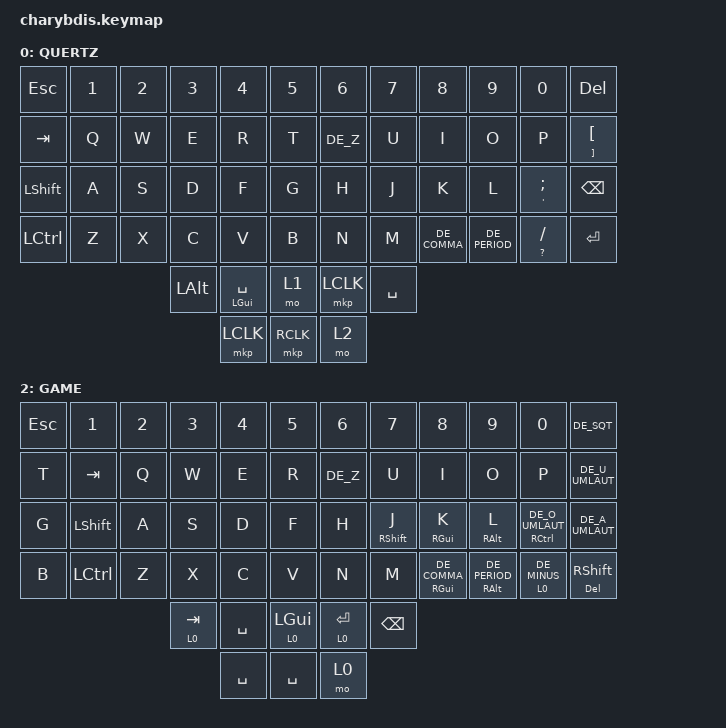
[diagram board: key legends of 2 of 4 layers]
#include "keys_de_swiss.h"
#include <dt-bindings/zmk/mouse.h>
#include <behaviors.dtsi>
#include <dt-bindings/zmk/bt.h>
#include <dt-bindings/zmk/ext_power.h>
#include <dt-bindings/zmk/keys.h>
#include <dt-bindings/zmk/pointing.h>
#include <input/processors.dtsi>
#include <dt-bindings/zmk/input_transform.h>

/ {
    /* ================= COMBOS ================== */

    combos {
        compatible = "zmk,combos";

        to-WIN {
            bindings = <&to 0>;
            key-positions = <50 51>;
            layers = <2 3>;
        };

        to-GAME {
            bindings = <&to 2>;
            key-positions = <47 36>;
            layers = <0 3>;
        };

        to-FN {
            bindings = <&to 3>;
            key-positions = <41 42>;
            layers = <0 2>;
        };

        caps_word {
            bindings = <&caps_word>;
            key-positions = <31 28>;
        };

        // УБРАНЫ мышиные клики через комбо — нестабильная конструкция
    };

    /* ================= BEHAVIORS ================= */

    behaviors {
        hmr: hmr {
            compatible = "zmk,behavior-hold-tap";
            label = "HMR";
            bindings = <&kp>, <&kp>;

            #binding-cells = <2>;
            tapping-term-ms = <190>;
            quick-tap-ms = <175>;
            flavor = "balanced";
            hold-trigger-key-positions = <36 37 38 39 40 41>; // ИСПРАВЛЕНО: только противоположная рука
            hold-trigger-on-release;
        };

        hml: hml {
            compatible = "zmk,behavior-hold-tap";
            label = "HML";
            bindings = <&kp>, <&kp>;

            #binding-cells = <2>;
            tapping-term-ms = <190>;
            quick-tap-ms = <175>;
            flavor = "balanced";
            hold-trigger-key-positions = <0 1 2 3 4 5>; // ИСПРАВЛЕНО: минимальный безопасный список
            hold-trigger-on-release;
        };
    };

    /* ================= TRACKBALL / MOUSE ================= */

    trackball_listener {
        compatible = "zmk,input-listener";
        device = <&trackball_split>;

        snipe {
            layers = <3>; /* Mouse layer */
            input-processors = <&zip_xy_scaler 1 3>;
        };

        scroll {
            layers = <2>; /* Nav layer */
            input-processors = <&zip_xy_scaler 1 3>, <&zip_xy_to_scroll_mapper>, <&zip_scroll_transform (INPUT_TRANSFORM_Y_INVERT)>;
        };
    };

    chosen {
        zmk,matrix_transform = &four_column_transform; /* 4×6 */
    };

    /* ================= KEYMAP ================= */

    keymap {
        compatible = "zmk,keymap";

        default_win_layer {
            label = "QUERTZ";
            bindings = <
&kp ESCAPE      &kp N1  &kp N2  &kp N3        &kp N4               &kp N5       &kp N6     &kp N7     &kp N8        &kp N9         &kp N0                &kp DELETE
&kp TAB         &kp Q   &kp W   &kp E         &kp R                &kp T        &kp DE_Z   &kp U      &kp I         &kp O          &kp P                 &hmr RBKT LBKT
&kp LEFT_SHIFT  &kp A   &kp S   &kp D         &kp F                &kp G        &kp H      &kp J      &kp K         &kp L          &hmr APOSTROPHE SEMI  &kp BACKSPACE
&kp LCTRL       &kp Z   &kp X   &kp C         &kp V                &kp B        &kp N      &kp M      &kp DE_COMMA  &kp DE_PERIOD  &hmr QMARK FSLH       &kp ENTER
                                &kp LEFT_ALT  &hmr LEFT_GUI SPACE  &mo 1        &mkp LCLK  &kp SPACE
                                              &mkp LCLK            &mkp RCLK    &mo 2
            >;
        };

        win_raise_layer {
            label = "NUMBERS";
            bindings = <
&kp F1        &kp F2                &kp F3       &kp F4                              &kp F5                                &kp F6           &kp F7           &kp F8  &kp F9  &kp F10  &kp F11        &kp F12
&trans        &kp HOME              &kp PAGE_UP  &kp UP                              &kp PAGE_DOWN                         &kp END          &kp FSLH         &kp N7  &kp N8  &kp N9   &kp MINUS      &trans
&trans        &hml LEFT_CONTROL N1  &kp LEFT     &kp DOWN                            &kp RIGHT                             &kp DE_TILDE     &kp DE_ASTERISK  &kp N4  &kp N5  &kp N6   &kp PLUS       &trans
&kp DE_CARET  &trans                &kp DE_AT    &hml DE_LEFT_BRACKET DE_LEFT_BRACE  &hml DE_RIGHT_BRACKET DE_RIGHT_BRACE  &kp DE_UMLAUT    &kp N0           &kp N1  &kp N2  &kp N3   &kp DE_PERIOD  &kp ENTER
            >;
        };

        default_game_layer {
            label = "GAME";
            bindings = <
&kp ESCAPE  &kp N1            &kp N2  &kp N3     &kp N4     &kp N5            &kp N6       &kp N7              &kp N8                   &kp N9                    &kp N0                          &kp DE_SQT
&kp T      &kp TAB           &kp Q   &kp W      &kp E      &kp R             &kp DE_Z     &kp U               &kp I                    &kp O                     &kp P                           &kp DE_U_UMLAUT
&kp G      &kp LEFT_SHIFT    &kp A   &kp S      &kp D      &kp F             &kp H        &hmr RIGHT_SHIFT J  &hmr RIGHT_GUI K         &hmr RIGHT_ALT L          &hmr RIGHT_CONTROL DE_O_UMLAUT  &kp DE_A_UMLAUT
&kp B      &kp LEFT_CONTROL  &kp Z   &kp X      &kp C      &kp V             &kp N        &kp M               &hmr RIGHT_GUI DE_COMMA  &hmr RIGHT_ALT DE_PERIOD  &lt 0 DE_MINUS                  &hmr DELETE RIGHT_SHIFT
                                      &lt 0 TAB  &kp SPACE  &lt 0 LEFT_GUI    &lt 0 ENTER  &kp BACKSPACE
                                                 &kp SPACE  &kp SPACE         &mo 0
            >;
        };

        keeb_pref_layer {
            label = "FN";
            bindings = <
&ext_power EP_TOG  &trans        &trans        &trans        &trans        &trans          &trans  &trans  &trans  &trans  &trans  &trans
&trans             &trans        &trans        &trans        &trans        &trans          &trans  &trans  &trans  &trans  &trans  &trans
&bt BT_CLR         &bt BT_SEL 0  &bt BT_SEL 1  &bt BT_SEL 2  &bt BT_SEL 3  &bt BT_SEL 4    &trans  &trans  &trans  &trans  &trans  &trans
&trans             &trans        &trans        &trans        &trans        &trans          &trans  &trans  &trans  &trans  &trans  &trans
            >;
        };
    };
};
